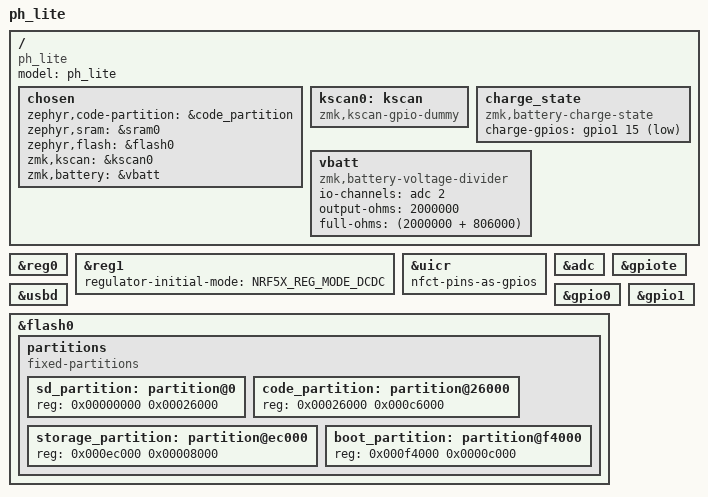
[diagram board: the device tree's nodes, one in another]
/*
 * Copyright (c) 2021 The ZMK Contributors
 *
 * SPDX-License-Identifier: MIT
 */

/dts-v1/;

#include <nordic/nrf52840_qiaa.dtsi>
#include <common/nordic/nrf52840_uf2_boot_mode.dtsi>

/ {
    model = "ph_lite";
    compatible = "ph_lite";

    chosen {
        zephyr,code-partition = &code_partition;
        zephyr,sram = &sram0;
        zephyr,flash = &flash0;
        zmk,kscan = &kscan0;
        zmk,battery = &vbatt;
    };

    kscan0: kscan {
        compatible = "zmk,kscan-gpio-dummy";
    };

    charge_state: charge_state {
        compatible = "zmk,battery-charge-state";
        charge-gpios = <&gpio1 15 GPIO_ACTIVE_LOW>;
    };

    /* Charger with 5 V buck output. The Evo shield selects VDDH instead. */
    vbatt: vbatt {
        compatible = "zmk,battery-voltage-divider";
        io-channels = <&adc 2>;
        output-ohms = <2000000>;
        full-ohms = <(2000000 + 806000)>;
    };
};

&reg0 {
    status = "okay";
};

&reg1 {
    regulator-initial-mode = <NRF5X_REG_MODE_DCDC>;
};

&uicr {
    nfct-pins-as-gpios;
};

&adc {
    status = "okay";
};

&gpiote {
    status = "okay";
};

&gpio0 {
    status = "okay";
};

&gpio1 {
    status = "okay";
};

zephyr_udc0: &usbd {
    status = "okay";
};

&flash0 {
    partitions {
        compatible = "fixed-partitions";
        #address-cells = <1>;
        #size-cells = <1>;

        sd_partition: partition@0 {
            reg = <0x00000000 0x00026000>;
        };
        code_partition: partition@26000 {
            reg = <0x00026000 0x000c6000>;
        };

        /* NVS settings must remain at the 3.5 address across UF2 updates. */
        storage_partition: partition@ec000 {
            reg = <0x000ec000 0x00008000>;
        };

        boot_partition: partition@f4000 {
            reg = <0x000f4000 0x0000c000>;
        };
    };
};
